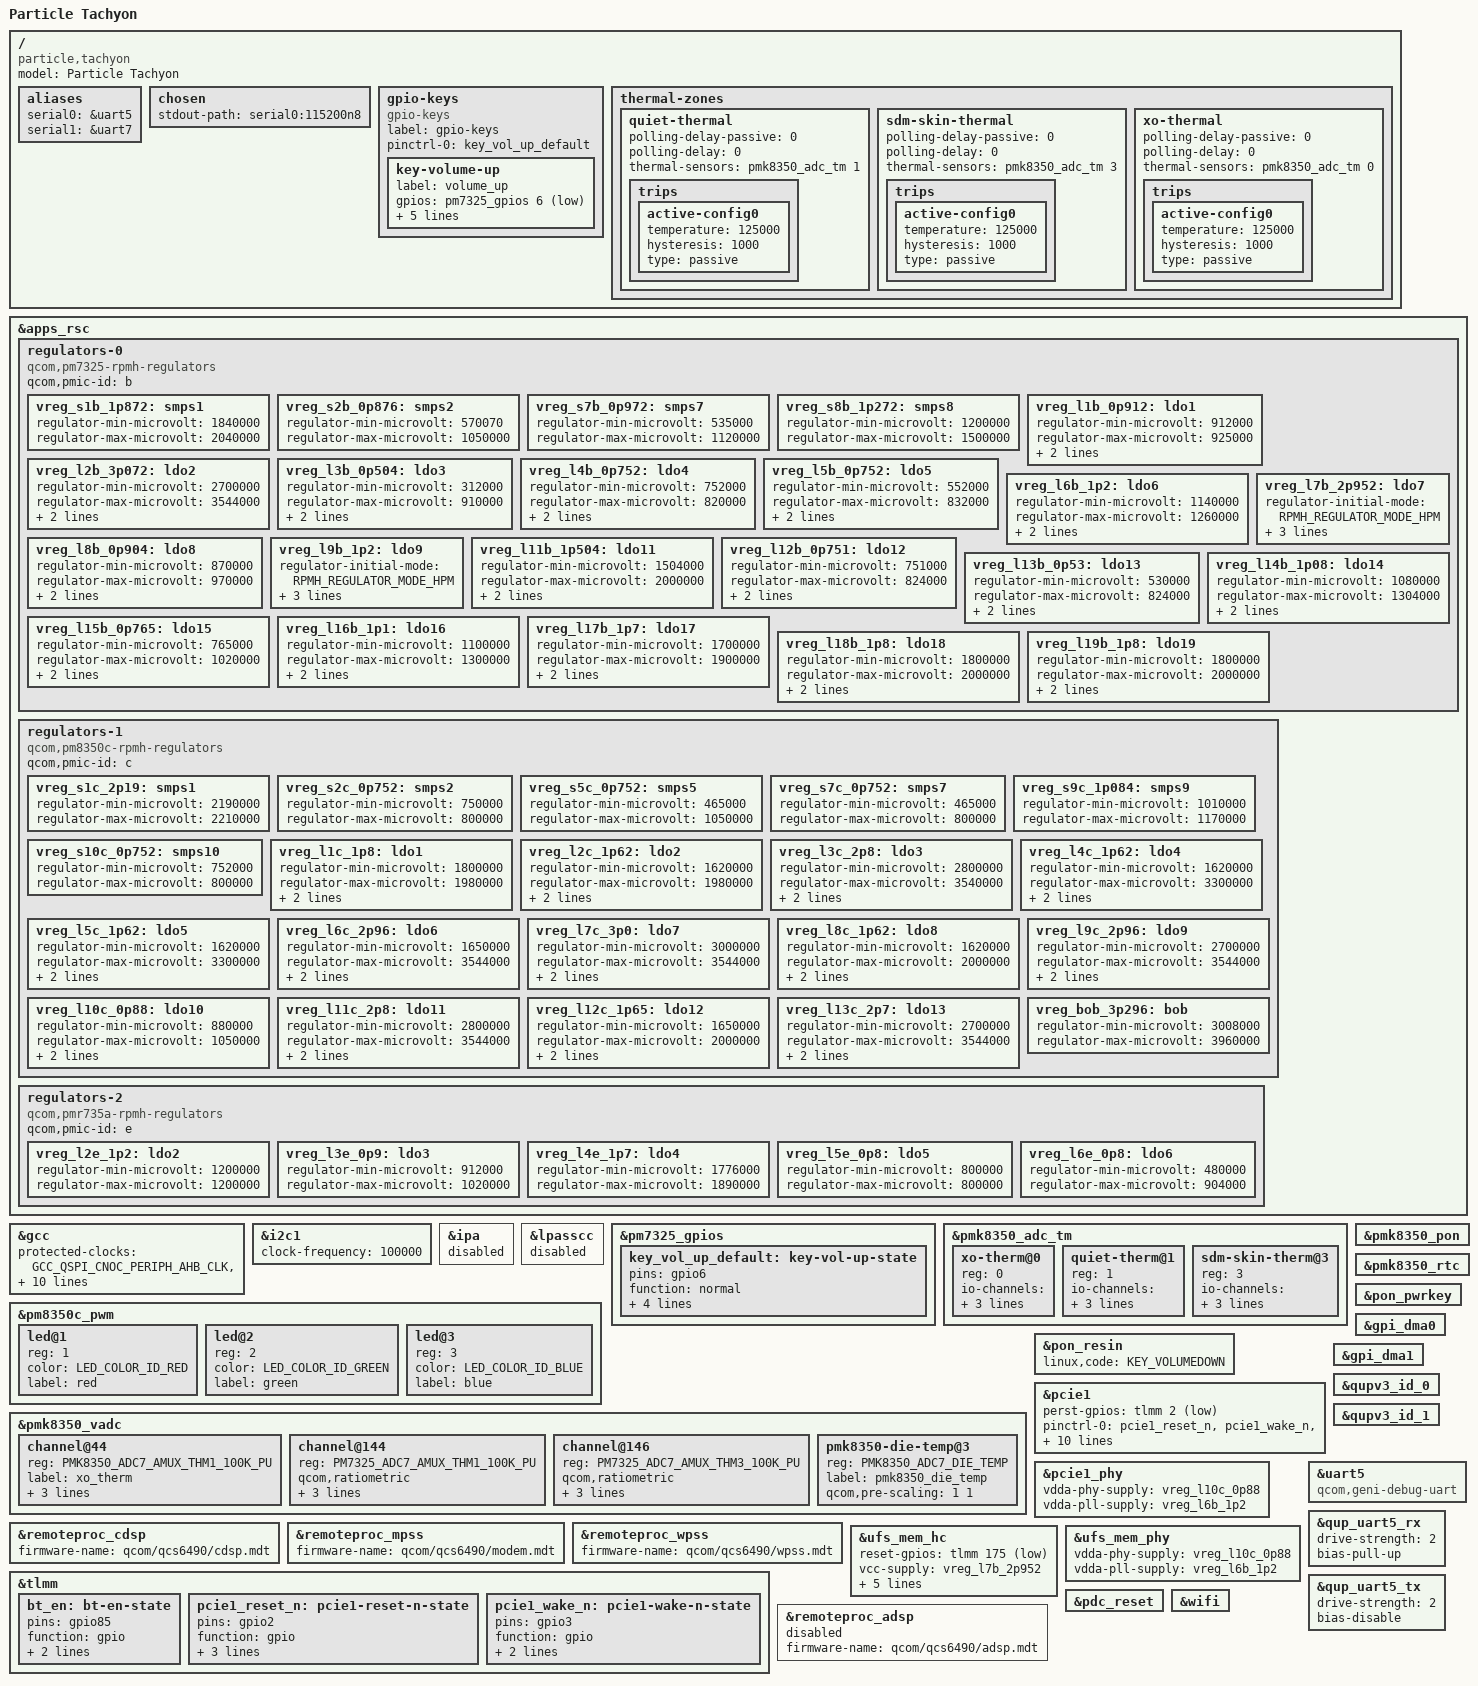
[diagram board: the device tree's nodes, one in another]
// SPDX-License-Identifier: BSD-3-Clause
/*
 * Copyright (c) 2023-2024 Qualcomm Innovation Center, Inc. All rights reserved.
 */

/dts-v1/;

/* PM7250B is configured to use SID8/9 */
#define PM7250B_SID 8
#define PM7250B_SID1 9

#include <dt-bindings/iio/qcom,spmi-adc7-pm7325.h>
#include <dt-bindings/iio/qcom,spmi-adc7-pmk8350.h>
#include <dt-bindings/input/linux-event-codes.h>
#include <dt-bindings/leds/common.h>
#include <dt-bindings/pinctrl/qcom,pmic-gpio.h>
#include <dt-bindings/regulator/qcom,rpmh-regulator.h>
#include <dt-bindings/iio/qcom,spmi-adc7-pmr735a.h>
#include "qcm6490_1.dtsi"
#include "pm7250b.dtsi"
#include "pm7325.dtsi"
#include "pm8350c.dtsi"
#include "pmk8350.dtsi"
#include "pmr735a.dtsi"


// FIXME
/delete-node/ &usb_2_dwc3;
/delete-node/ &eud;

/ {
	model = "Particle Tachyon";
	compatible = "particle,tachyon", "qcom,qcm6490";


	aliases {
		serial0 = &uart5;
		serial1 = &uart7;
	};

	chosen {
		stdout-path = "serial0:115200n8";
	};

	gpio-keys {
		compatible = "gpio-keys";
		label = "gpio-keys";

		pinctrl-0 = <&key_vol_up_default>;
		pinctrl-names = "default";

		key-volume-up {
			label = "volume_up";
			gpios = <&pm7325_gpios 6 GPIO_ACTIVE_LOW>;
			linux,input-type = <1>;
			linux,code = <KEY_VOLUMEUP>;
			wakeup-source;
			debounce-interval = <15>;
			linux,can-disable;
		};
	};

	thermal-zones {
		quiet-thermal {
			polling-delay-passive = <0>;
			polling-delay = <0>;
			thermal-sensors = <&pmk8350_adc_tm 1>;

			trips {
				active-config0 {
					temperature = <125000>;
					hysteresis = <1000>;
					type = "passive";
				};
			};
		};

		sdm-skin-thermal {
			polling-delay-passive = <0>;
			polling-delay = <0>;
			thermal-sensors = <&pmk8350_adc_tm 3>;

			trips {
				active-config0 {
					temperature = <125000>;
					hysteresis = <1000>;
					type = "passive";
				};
			};
		};

		xo-thermal {
			polling-delay-passive = <0>;
			polling-delay = <0>;
			thermal-sensors = <&pmk8350_adc_tm 0>;

			trips {
				active-config0 {
					temperature = <125000>;
					hysteresis = <1000>;
					type = "passive";
				};
			};
		};
	};
};

&apps_rsc {
	regulators-0 {
		compatible = "qcom,pm7325-rpmh-regulators";
		qcom,pmic-id = "b";

		vreg_s1b_1p872: smps1 {
			regulator-min-microvolt = <1840000>;
			regulator-max-microvolt = <2040000>;
		};

		vreg_s2b_0p876: smps2 {
			regulator-min-microvolt = <570070>;
			regulator-max-microvolt = <1050000>;
		};

		vreg_s7b_0p972: smps7 {
			regulator-min-microvolt = <535000>;
			regulator-max-microvolt = <1120000>;
		};

		vreg_s8b_1p272: smps8 {
			regulator-min-microvolt = <1200000>;
			regulator-max-microvolt = <1500000>;
		};

		vreg_l1b_0p912: ldo1 {
			regulator-min-microvolt = <912000>;
			regulator-max-microvolt = <925000>;
			regulator-initial-mode = <RPMH_REGULATOR_MODE_HPM>;
		};

		vreg_l2b_3p072: ldo2 {
			regulator-min-microvolt = <2700000>;
			regulator-max-microvolt = <3544000>;
			regulator-initial-mode = <RPMH_REGULATOR_MODE_HPM>;
		};

		vreg_l3b_0p504: ldo3 {
			regulator-min-microvolt = <312000>;
			regulator-max-microvolt = <910000>;
			regulator-initial-mode = <RPMH_REGULATOR_MODE_HPM>;
		};

		vreg_l4b_0p752: ldo4 {
			regulator-min-microvolt = <752000>;
			regulator-max-microvolt = <820000>;
			regulator-initial-mode = <RPMH_REGULATOR_MODE_HPM>;
		};

		vreg_l5b_0p752: ldo5 {
			regulator-min-microvolt = <552000>;
			regulator-max-microvolt = <832000>;
			regulator-initial-mode = <RPMH_REGULATOR_MODE_HPM>;
		};

		vreg_l6b_1p2: ldo6 {
			regulator-min-microvolt = <1140000>;
			regulator-max-microvolt = <1260000>;
			regulator-initial-mode = <RPMH_REGULATOR_MODE_HPM>;
		};

		vreg_l7b_2p952: ldo7 {
			regulator-min-microvolt = <2400000>;
			regulator-max-microvolt = <3544000>;
			regulator-initial-mode = <RPMH_REGULATOR_MODE_HPM>;
		};

		vreg_l8b_0p904: ldo8 {
			regulator-min-microvolt = <870000>;
			regulator-max-microvolt = <970000>;
			regulator-initial-mode = <RPMH_REGULATOR_MODE_HPM>;
		};

		vreg_l9b_1p2: ldo9 {
			regulator-min-microvolt = <1200000>;
			regulator-max-microvolt = <1304000>;
			regulator-initial-mode = <RPMH_REGULATOR_MODE_HPM>;
		};

		vreg_l11b_1p504: ldo11 {
			regulator-min-microvolt = <1504000>;
			regulator-max-microvolt = <2000000>;
			regulator-initial-mode = <RPMH_REGULATOR_MODE_HPM>;
		};

		vreg_l12b_0p751: ldo12 {
			regulator-min-microvolt = <751000>;
			regulator-max-microvolt = <824000>;
			regulator-initial-mode = <RPMH_REGULATOR_MODE_HPM>;
		};

		vreg_l13b_0p53: ldo13 {
			regulator-min-microvolt = <530000>;
			regulator-max-microvolt = <824000>;
			regulator-initial-mode = <RPMH_REGULATOR_MODE_HPM>;
		};

		vreg_l14b_1p08: ldo14 {
			regulator-min-microvolt = <1080000>;
			regulator-max-microvolt = <1304000>;
			regulator-initial-mode = <RPMH_REGULATOR_MODE_HPM>;
		};

		vreg_l15b_0p765: ldo15 {
			regulator-min-microvolt = <765000>;
			regulator-max-microvolt = <1020000>;
			regulator-initial-mode = <RPMH_REGULATOR_MODE_HPM>;
		};

		vreg_l16b_1p1: ldo16 {
			regulator-min-microvolt = <1100000>;
			regulator-max-microvolt = <1300000>;
			regulator-initial-mode = <RPMH_REGULATOR_MODE_HPM>;
		};

		vreg_l17b_1p7: ldo17 {
			regulator-min-microvolt = <1700000>;
			regulator-max-microvolt = <1900000>;
			regulator-initial-mode = <RPMH_REGULATOR_MODE_HPM>;
		};

		vreg_l18b_1p8: ldo18 {
			regulator-min-microvolt = <1800000>;
			regulator-max-microvolt = <2000000>;
			regulator-initial-mode = <RPMH_REGULATOR_MODE_HPM>;
		};

		vreg_l19b_1p8: ldo19 {
			regulator-min-microvolt = <1800000>;
			regulator-max-microvolt = <2000000>;
			regulator-initial-mode = <RPMH_REGULATOR_MODE_HPM>;
		};
	};

	regulators-1 {
		compatible = "qcom,pm8350c-rpmh-regulators";
		qcom,pmic-id = "c";

		vreg_s1c_2p19: smps1 {
			regulator-min-microvolt = <2190000>;
			regulator-max-microvolt = <2210000>;
		};

		vreg_s2c_0p752: smps2 {
			regulator-min-microvolt = <750000>;
			regulator-max-microvolt = <800000>;
		};

		vreg_s5c_0p752: smps5 {
			regulator-min-microvolt = <465000>;
			regulator-max-microvolt = <1050000>;
		};

		vreg_s7c_0p752: smps7 {
			regulator-min-microvolt = <465000>;
			regulator-max-microvolt = <800000>;
		};

		vreg_s9c_1p084: smps9 {
			regulator-min-microvolt = <1010000>;
			regulator-max-microvolt = <1170000>;
		};

		vreg_s10c_0p752:smps10 {
			regulator-min-microvolt = <752000>;
			regulator-max-microvolt = <800000>;
		};

		vreg_l1c_1p8: ldo1 {
			regulator-min-microvolt = <1800000>;
			regulator-max-microvolt = <1980000>;
			regulator-initial-mode = <RPMH_REGULATOR_MODE_HPM>;
		};

		vreg_l2c_1p62: ldo2 {
			regulator-min-microvolt = <1620000>;
			regulator-max-microvolt = <1980000>;
			regulator-initial-mode = <RPMH_REGULATOR_MODE_HPM>;
		};

		vreg_l3c_2p8: ldo3 {
			regulator-min-microvolt = <2800000>;
			regulator-max-microvolt = <3540000>;
			regulator-initial-mode = <RPMH_REGULATOR_MODE_HPM>;
		};

		vreg_l4c_1p62: ldo4 {
			regulator-min-microvolt = <1620000>;
			regulator-max-microvolt = <3300000>;
			regulator-initial-mode = <RPMH_REGULATOR_MODE_HPM>;
		};

		vreg_l5c_1p62: ldo5 {
			regulator-min-microvolt = <1620000>;
			regulator-max-microvolt = <3300000>;
			regulator-initial-mode = <RPMH_REGULATOR_MODE_HPM>;
		};

		vreg_l6c_2p96: ldo6 {
			regulator-min-microvolt = <1650000>;
			regulator-max-microvolt = <3544000>;
			regulator-initial-mode = <RPMH_REGULATOR_MODE_HPM>;
		};

		vreg_l7c_3p0: ldo7 {
			regulator-min-microvolt = <3000000>;
			regulator-max-microvolt = <3544000>;
			regulator-initial-mode = <RPMH_REGULATOR_MODE_HPM>;
		};

		vreg_l8c_1p62: ldo8 {
			regulator-min-microvolt = <1620000>;
			regulator-max-microvolt = <2000000>;
			regulator-initial-mode = <RPMH_REGULATOR_MODE_HPM>;
		};

		vreg_l9c_2p96: ldo9 {
			regulator-min-microvolt = <2700000>;
			regulator-max-microvolt = <3544000>;
			regulator-initial-mode = <RPMH_REGULATOR_MODE_HPM>;
		};

		vreg_l10c_0p88: ldo10 {
			regulator-min-microvolt = <880000>;
			regulator-max-microvolt = <1050000>;
			regulator-initial-mode = <RPMH_REGULATOR_MODE_HPM>;
		};

		vreg_l11c_2p8: ldo11 {
			regulator-min-microvolt = <2800000>;
			regulator-max-microvolt = <3544000>;
			regulator-initial-mode = <RPMH_REGULATOR_MODE_HPM>;
		};

		vreg_l12c_1p65: ldo12 {
			regulator-min-microvolt = <1650000>;
			regulator-max-microvolt = <2000000>;
			regulator-initial-mode = <RPMH_REGULATOR_MODE_HPM>;
		};

		vreg_l13c_2p7: ldo13 {
			regulator-min-microvolt = <2700000>;
			regulator-max-microvolt = <3544000>;
			regulator-initial-mode = <RPMH_REGULATOR_MODE_HPM>;
		};

		vreg_bob_3p296: bob {
			regulator-min-microvolt = <3008000>;
			regulator-max-microvolt = <3960000>;
		};
	};
	regulators-2 {
		compatible = "qcom,pmr735a-rpmh-regulators";
		qcom,pmic-id = "e";

		vreg_l2e_1p2: ldo2 {
			regulator-min-microvolt = <1200000>;
			regulator-max-microvolt = <1200000>;
		};

		vreg_l3e_0p9: ldo3 {
			regulator-min-microvolt = <912000>;
			regulator-max-microvolt = <1020000>;
		};

		vreg_l4e_1p7: ldo4 {
			regulator-min-microvolt = <1776000>;
			regulator-max-microvolt = <1890000>;
		};

		vreg_l5e_0p8: ldo5 {
			regulator-min-microvolt = <800000>;
			regulator-max-microvolt = <800000>;
		};

		vreg_l6e_0p8: ldo6 {
			regulator-min-microvolt = <480000>;
			regulator-max-microvolt = <904000>;
		};
	};
};

&gcc {
	protected-clocks = <GCC_QSPI_CNOC_PERIPH_AHB_CLK>, <GCC_QSPI_CORE_CLK>,
			<GCC_QSPI_CORE_CLK_SRC>, <GCC_CFG_NOC_LPASS_CLK>,
			<GCC_MSS_GPLL0_MAIN_DIV_CLK_SRC>, <GCC_MSS_CFG_AHB_CLK>,
			<GCC_MSS_OFFLINE_AXI_CLK>, <GCC_MSS_SNOC_AXI_CLK>,
			<GCC_MSS_Q6_MEMNOC_AXI_CLK>, <GCC_MSS_Q6SS_BOOT_CLK_SRC>,
			<GCC_SEC_CTRL_CLK_SRC>, <GCC_WPSS_AHB_CLK>,
			<GCC_WPSS_AHB_BDG_MST_CLK>, <GCC_WPSS_RSCP_CLK>;
};

&i2c1 {
	clock-frequency = <100000>;
	status = "okay";
};

&ipa {
	status = "disabled";
};

&lpasscc {
	status = "disabled";
};

&pm7325_gpios {
	key_vol_up_default: key-vol-up-state {
		pins = "gpio6";
		function = "normal";
		input-enable;
		bias-pull-up;
		power-source = <0>;
		qcom,drive-strength = <3>;
	};
};

&pm8350c_pwm {
	#address-cells = <1>;
	#size-cells = <0>;
	status = "okay";

	led@1 {
		reg = <1>;
		color = <LED_COLOR_ID_RED>;
		label = "red";
	};

	led@2 {
		reg = <2>;
		color = <LED_COLOR_ID_GREEN>;
		label = "green";
	};

	led@3 {
		reg = <3>;
		color = <LED_COLOR_ID_BLUE>;
		label = "blue";
	};
};

&pmk8350_adc_tm {
	status = "okay";

	xo-therm@0 {
		reg = <0>;
		io-channels = <&pmk8350_vadc PMK8350_ADC7_AMUX_THM1_100K_PU>;
		qcom,ratiometric;
		qcom,hw-settle-time-us = <200>;
	};

	quiet-therm@1 {
		reg = <1>;
		io-channels = <&pmk8350_vadc PM7325_ADC7_AMUX_THM1_100K_PU>;
		qcom,ratiometric;
		qcom,hw-settle-time-us = <200>;
	};

	sdm-skin-therm@3 {
		reg = <3>;
		io-channels = <&pmk8350_vadc PM7325_ADC7_AMUX_THM3_100K_PU>;
		qcom,ratiometric;
		qcom,hw-settle-time-us = <200>;
	};
};

&pmk8350_pon {
	status = "okay";
};

&pmk8350_rtc {
	status = "okay";
};

&pmk8350_vadc {
	channel@44 {
		reg = <PMK8350_ADC7_AMUX_THM1_100K_PU>;
		label = "xo_therm";
		qcom,hw-settle-time = <200>;
		qcom,pre-scaling = <1 1>;
		qcom,ratiometric;
	};

	channel@144 {
		reg = <PM7325_ADC7_AMUX_THM1_100K_PU>;
		qcom,ratiometric;
		qcom,hw-settle-time = <200>;
		qcom,pre-scaling = <1 1>;
		label = "pm7325_quiet_therm";
	};

	channel@146 {
		reg = <PM7325_ADC7_AMUX_THM3_100K_PU>;
		qcom,ratiometric;
		qcom,hw-settle-time = <200>;
		qcom,pre-scaling = <1 1>;
		label = "pm7325_sdm_skin_therm";
	};

	pmk8350-die-temp@3 {
		reg = <PMK8350_ADC7_DIE_TEMP>;
		label = "pmk8350_die_temp";
		qcom,pre-scaling = <1 1>;
	};
};

&pon_pwrkey {
	status = "okay";
};

&pon_resin {
	linux,code = <KEY_VOLUMEDOWN>;
	status = "okay";
};

&pcie1 {
	perst-gpios = <&tlmm 2 GPIO_ACTIVE_LOW>;

	// GPIO13 needed too
	pinctrl-0 = <&pcie1_reset_n>, <&pcie1_wake_n>, <&pcie1_clkreq_n>;
	pinctrl-names = "default";

	iommu-map = <0x0 &apps_smmu 0x1c80 0x1>,
		    <0x100 &apps_smmu 0x1c81 0x1>,
		    <0x208 &apps_smmu 0x1c84 0x1>,
		    <0x210 &apps_smmu 0x1c85 0x1>,
		    <0x218 &apps_smmu 0x1c86 0x1>,
		    <0x300 &apps_smmu 0x1c87 0x1>,
		    <0x400 &apps_smmu 0x1c88 0x1>,
		    <0x500 &apps_smmu 0x1c89 0x1>,
		    <0x501 &apps_smmu 0x1c90 0x1>;

	status = "okay";
};

&pcie1_phy {
	vdda-phy-supply = <&vreg_l10c_0p88>;
	vdda-pll-supply = <&vreg_l6b_1p2>;

	status = "okay";
};

&gpi_dma0 {
	status = "okay";
};

&gpi_dma1 {
	status = "okay";
};

&qupv3_id_0 {
	status = "okay";
};

&qupv3_id_1 {
	status = "okay";
};

&remoteproc_cdsp {
	firmware-name = "qcom/qcs6490/cdsp.mdt";
	status = "okay";
};

&remoteproc_mpss {
	firmware-name = "qcom/qcs6490/modem.mdt";
	status = "okay";
};

&remoteproc_wpss {
	firmware-name = "qcom/qcs6490/wpss.mdt";
	status = "okay";
};

&tlmm {
	bt_en: bt-en-state {
		pins = "gpio85";
		function = "gpio";
		output-low;
		bias-disable;
	};

	pcie1_reset_n: pcie1-reset-n-state {
		pins = "gpio2";
		function = "gpio";
		drive-strength = <16>;
		output-low;
		bias-disable;
	};

	pcie1_wake_n: pcie1-wake-n-state {
		pins = "gpio3";
		function = "gpio";
		drive-strength = <2>;
		bias-pull-up;
	};
};

&ufs_mem_hc {
	reset-gpios = <&tlmm 175 GPIO_ACTIVE_LOW>;
	vcc-supply = <&vreg_l7b_2p952>;
	vcc-max-microamp = <800000>;
	vccq-supply = <&vreg_l9b_1p2>;
	vccq-max-microamp = <900000>;
	vccq2-supply = <&vreg_l9b_1p2>;
	vccq2-max-microamp = <900000>;

	status = "okay";
};

&ufs_mem_phy {
	vdda-phy-supply = <&vreg_l10c_0p88>;
	vdda-pll-supply = <&vreg_l6b_1p2>;

	status = "okay";
};

/delete-node/ &usb_1_dwc3;

&vreg_l7b_2p952 {
	/delete-property/regulator-min-microvolt;
	/delete-property/regulator-max-microvolt;
	regulator-allow-set-load;
	regulator-allowed-modes = <RPMH_REGULATOR_MODE_LPM RPMH_REGULATOR_MODE_HPM>;
};

&vreg_l9b_1p2 {
	/delete-property/regulator-min-microvolt;
	/delete-property/regulator-max-microvolt;
	regulator-allow-set-load;
	regulator-allowed-modes = <RPMH_REGULATOR_MODE_LPM RPMH_REGULATOR_MODE_HPM>;
};

&uart5 {
	compatible = "qcom,geni-debug-uart";
	status = "okay";
};

&qup_uart5_rx {
	drive-strength = <2>;
	bias-pull-up;
};

&qup_uart5_tx {
	drive-strength = <2>;
	bias-disable;
};

&pcie1 {
	perst-gpios = <&tlmm 2 GPIO_ACTIVE_LOW>;

	pinctrl-0 = <&pcie1_reset_n>, <&pcie1_wake_n>, <&pcie1_clkreq_n>;
	pinctrl-names = "default";

	iommu-map = <0x0 &apps_smmu 0x1c80 0x1>,
		    <0x100 &apps_smmu 0x1c81 0x1>,
		    <0x208 &apps_smmu 0x1c84 0x1>,
		    <0x210 &apps_smmu 0x1c85 0x1>,
		    <0x218 &apps_smmu 0x1c86 0x1>,
		    <0x300 &apps_smmu 0x1c87 0x1>,
		    <0x400 &apps_smmu 0x1c88 0x1>,
		    <0x500 &apps_smmu 0x1c89 0x1>,
		    <0x501 &apps_smmu 0x1c90 0x1>;

	status = "okay";
};

&pcie1_phy {
	vdda-phy-supply = <&vreg_l10c_0p88>;
	vdda-pll-supply = <&vreg_l6b_1p2>;

	status = "okay";
};

&pdc_reset {
	status = "okay";
};

&remoteproc_wpss {
    firmware-name = "qcom/qcs6490/wpss.mdt";
	status = "okay";
};

// &remoteproc_adsp {
// 	compatible = "qcom,sc7280-adsp-pil";
// 	clocks = <&rpmhcc RPMH_CXO_CLK>,
// 			<&gcc GCC_CFG_NOC_LPASS_CLK>;
// 	clock-names = "xo", "gcc_cfg_noc_lpass";

// 	resets = <&pdc_reset PDC_AUDIO_SYNC_RESET>,
//                  <&aoss_reset AOSS_CC_LPASS_RESTART>;
// 	reset-names = "pdc_sync", "cc_lpass";

// 	qcom,halt-regs = <&tcsr_mutex 0x23000 0x25000 0x28000 0x33000>;

// 	firmware-name = "qcom/tachyon/adsp.mdt";
// 	status = "okay";
// };

&remoteproc_adsp {
	firmware-name = "qcom/qcs6490/adsp.mdt";
	status = "disabled";
};

&wifi {
    status = "okay";
};
